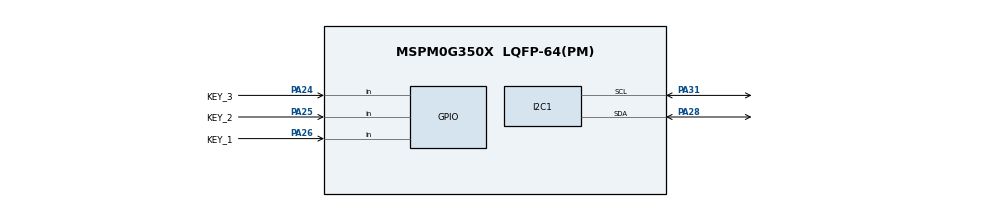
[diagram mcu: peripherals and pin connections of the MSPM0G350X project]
/**
 *
 * @cliArgs --device "MSPM0G350X" --part "Default" --package "LQFP-64(PM)" --product "mspm0_sdk@2.10.00.04"
 * @versions {"tool":"1.28.0+4696"}
 */

/**
 * Import the modules used in this configuration.
 */
const DMA     = scripting.addModule("/ti/driverlib/DMA");
const GPIO    = scripting.addModule("/ti/driverlib/GPIO", {}, false);
const GPIO1   = GPIO.addInstance();
const GPIO2   = GPIO.addInstance();
const GPIO3   = GPIO.addInstance();
const GPIO4   = GPIO.addInstance();
const GPIO5   = GPIO.addInstance();
const I2C     = scripting.addModule("/ti/driverlib/I2C", {}, false);
const I2C1    = I2C.addInstance();
const PWM     = scripting.addModule("/ti/driverlib/PWM", {}, false);
const PWM1    = PWM.addInstance();
const SYSCTL  = scripting.addModule("/ti/driverlib/SYSCTL");
const SYSTICK = scripting.addModule("/ti/driverlib/SYSTICK");
const TIMER   = scripting.addModule("/ti/driverlib/TIMER", {}, false);
const TIMER1  = TIMER.addInstance();
const UART    = scripting.addModule("/ti/driverlib/UART", {}, false);
const UART1   = UART.addInstance();
const UART2   = UART.addInstance();
const UART3   = UART.addInstance();
const UART4   = UART.addInstance();

/**
 * Write custom configuration values to the imported modules.
 */
const divider6       = system.clockTree["PLL_CLK2X_DIV"];
divider6.divideValue = 4;

const divider7       = system.clockTree["PLL_PDIV"];
divider7.divideValue = 2;

const divider9       = system.clockTree["UDIV"];
divider9.divideValue = 2;

const multiplier2         = system.clockTree["PLL_QDIV"];
multiplier2.multiplyValue = 10;

const mux8       = system.clockTree["HSCLKMUX"];
mux8.inputSelect = "HSCLKMUX_SYSPLL2X";

const Board = scripting.addModule("/ti/driverlib/Board", {}, false);

GPIO1.$name                         = "ENCODERA";
GPIO1.associatedPins.create(2);
GPIO1.associatedPins[0].$name       = "E1A";
GPIO1.associatedPins[0].direction   = "INPUT";
GPIO1.associatedPins[0].interruptEn = true;
GPIO1.associatedPins[0].polarity    = "RISE_FALL";
GPIO1.associatedPins[1].$name       = "E1B";
GPIO1.associatedPins[1].direction   = "INPUT";
GPIO1.associatedPins[1].interruptEn = true;
GPIO1.associatedPins[1].polarity    = "RISE_FALL";

GPIO2.$name                         = "ENCODERB";
GPIO2.associatedPins.create(2);
GPIO2.associatedPins[0].$name       = "E2A";
GPIO2.associatedPins[0].direction   = "INPUT";
GPIO2.associatedPins[0].interruptEn = true;
GPIO2.associatedPins[0].polarity    = "RISE_FALL";
GPIO2.associatedPins[1].$name       = "E2B";
GPIO2.associatedPins[1].direction   = "INPUT";
GPIO2.associatedPins[1].interruptEn = true;
GPIO2.associatedPins[1].polarity    = "RISE_FALL";

GPIO3.$name                   = "AIN";
GPIO3.associatedPins.create(2);
GPIO3.associatedPins[0].$name = "AIN1";
GPIO3.associatedPins[1].$name = "AIN2";

GPIO4.$name                   = "BIN";
GPIO4.associatedPins.create(2);
GPIO4.associatedPins[0].$name = "BIN1";
GPIO4.associatedPins[1].$name = "BIN2";

GPIO5.$name                              = "KEY";
GPIO5.port                               = "PORTA";
GPIO5.associatedPins.create(3);
GPIO5.associatedPins[0].$name            = "KEY_1";
GPIO5.associatedPins[0].direction        = "INPUT";
GPIO5.associatedPins[0].internalResistor = "PULL_UP";
GPIO5.associatedPins[0].pin.$assign      = "PA26";
GPIO5.associatedPins[1].$name            = "KEY_2";
GPIO5.associatedPins[1].direction        = "INPUT";
GPIO5.associatedPins[1].internalResistor = "PULL_UP";
GPIO5.associatedPins[1].pin.$assign      = "PA25";
GPIO5.associatedPins[2].$name            = "KEY_3";
GPIO5.associatedPins[2].direction        = "INPUT";
GPIO5.associatedPins[2].internalResistor = "PULL_UP";
GPIO5.associatedPins[2].pin.$assign      = "PA24";

I2C1.$name                             = "I2C_OLED";
I2C1.basicEnableController             = true;
I2C1.basicControllerStandardBusSpeed   = "Fast";
I2C1.peripheral.sdaPin.$assign         = "PA28";
I2C1.peripheral.sclPin.$assign         = "PA31";
I2C1.sdaPinConfig.$name                = "ti_driverlib_gpio_GPIOPinGeneric10";
I2C1.sdaPinConfig.hideOutputInversion  = scripting.forceWrite(false);
I2C1.sdaPinConfig.onlyInternalResistor = scripting.forceWrite(false);
I2C1.sdaPinConfig.passedPeripheralType = scripting.forceWrite("Digital");
I2C1.sclPinConfig.$name                = "ti_driverlib_gpio_GPIOPinGeneric11";
I2C1.sclPinConfig.hideOutputInversion  = scripting.forceWrite(false);
I2C1.sclPinConfig.onlyInternalResistor = scripting.forceWrite(false);
I2C1.sclPinConfig.passedPeripheralType = scripting.forceWrite("Digital");

PWM1.$name               = "PWM_0";
PWM1.timerCount          = 8000;
PWM1.timerStartTimer     = true;
PWM1.pwmMode             = "EDGE_ALIGN_UP";
PWM1.PWM_CHANNEL_0.$name = "ti_driverlib_pwm_PWMTimerCC0";
PWM1.PWM_CHANNEL_1.$name = "ti_driverlib_pwm_PWMTimerCC1";
PWM1.ccp0PinConfig.$name = "ti_driverlib_gpio_GPIOPinGeneric0";
PWM1.ccp1PinConfig.$name = "ti_driverlib_gpio_GPIOPinGeneric1";

SYSCTL.forceDefaultClkConfig = true;
SYSCTL.clockTreeEn           = true;

SYSTICK.periodEnable  = true;
SYSTICK.period        = 80;
SYSTICK.systickEnable = true;

TIMER1.timerMode         = "PERIODIC";
TIMER1.timerPeriod       = "1 ms";
TIMER1.timerClkPrescale  = 8;
TIMER1.interrupts        = ["ZERO"];
TIMER1.interruptPriority = "2";
TIMER1.$name             = "TIMER_1ms";

UART1.enabledDMARXTriggers             = "DL_UART_DMA_INTERRUPT_RX";
UART1.$name                            = "UART_fpgaMLK";
UART1.txPinConfig.$name                = "ti_driverlib_gpio_GPIOPinGeneric2";
UART1.txPinConfig.direction            = scripting.forceWrite("OUTPUT");
UART1.txPinConfig.hideOutputInversion  = scripting.forceWrite(false);
UART1.txPinConfig.onlyInternalResistor = scripting.forceWrite(false);
UART1.txPinConfig.passedPeripheralType = scripting.forceWrite("Digital");
UART1.rxPinConfig.$name                = "ti_driverlib_gpio_GPIOPinGeneric3";
UART1.rxPinConfig.hideOutputInversion  = scripting.forceWrite(false);
UART1.rxPinConfig.onlyInternalResistor = scripting.forceWrite(false);
UART1.rxPinConfig.passedPeripheralType = scripting.forceWrite("Digital");
UART1.DMA_CHANNEL_RX.$name             = "DMA_fpgaMLK";

UART2.$name                            = "UART_left";
UART2.targetBaudRate                   = 115200;
UART2.enableFIFO                       = true;
UART2.enabledInterrupts                = ["FRAMING_ERROR","NOISE_ERROR","OVERRUN_ERROR","RX"];
UART2.rxFifoThreshold                  = "DL_UART_RX_FIFO_LEVEL_ONE_ENTRY";
UART2.txPinConfig.$name                = "ti_driverlib_gpio_GPIOPinGeneric4";
UART2.txPinConfig.direction            = scripting.forceWrite("OUTPUT");
UART2.txPinConfig.hideOutputInversion  = scripting.forceWrite(false);
UART2.txPinConfig.onlyInternalResistor = scripting.forceWrite(false);
UART2.txPinConfig.passedPeripheralType = scripting.forceWrite("Digital");
UART2.rxPinConfig.$name                = "ti_driverlib_gpio_GPIOPinGeneric5";
UART2.rxPinConfig.hideOutputInversion  = scripting.forceWrite(false);
UART2.rxPinConfig.onlyInternalResistor = scripting.forceWrite(false);
UART2.rxPinConfig.passedPeripheralType = scripting.forceWrite("Digital");

UART3.$name                            = "UART_forward";
UART3.targetBaudRate                   = 115200;
UART3.enableFIFO                       = true;
UART3.enabledInterrupts                = ["FRAMING_ERROR","NOISE_ERROR","OVERRUN_ERROR","RX"];
UART3.rxFifoThreshold                  = "DL_UART_RX_FIFO_LEVEL_ONE_ENTRY";
UART3.txPinConfig.$name                = "ti_driverlib_gpio_GPIOPinGeneric6";
UART3.txPinConfig.direction            = scripting.forceWrite("OUTPUT");
UART3.txPinConfig.hideOutputInversion  = scripting.forceWrite(false);
UART3.txPinConfig.onlyInternalResistor = scripting.forceWrite(false);
UART3.txPinConfig.passedPeripheralType = scripting.forceWrite("Digital");
UART3.rxPinConfig.$name                = "ti_driverlib_gpio_GPIOPinGeneric7";
UART3.rxPinConfig.hideOutputInversion  = scripting.forceWrite(false);
UART3.rxPinConfig.onlyInternalResistor = scripting.forceWrite(false);
UART3.rxPinConfig.passedPeripheralType = scripting.forceWrite("Digital");

UART4.$name                            = "UART_right";
UART4.targetBaudRate                   = 115200;
UART4.enableFIFO                       = true;
UART4.enabledInterrupts                = ["FRAMING_ERROR","NOISE_ERROR","OVERRUN_ERROR","RX"];
UART4.rxFifoThreshold                  = "DL_UART_RX_FIFO_LEVEL_ONE_ENTRY";
UART4.txPinConfig.$name                = "ti_driverlib_gpio_GPIOPinGeneric8";
UART4.txPinConfig.direction            = scripting.forceWrite("OUTPUT");
UART4.txPinConfig.hideOutputInversion  = scripting.forceWrite(false);
UART4.txPinConfig.onlyInternalResistor = scripting.forceWrite(false);
UART4.txPinConfig.passedPeripheralType = scripting.forceWrite("Digital");
UART4.rxPinConfig.$name                = "ti_driverlib_gpio_GPIOPinGeneric9";
UART4.rxPinConfig.hideOutputInversion  = scripting.forceWrite(false);
UART4.rxPinConfig.onlyInternalResistor = scripting.forceWrite(false);
UART4.rxPinConfig.passedPeripheralType = scripting.forceWrite("Digital");

/**
 * Pinmux solution for unlocked pins/peripherals. This ensures that minor changes to the automatic solver in a future
 * version of the tool will not impact the pinmux you originally saw.  These lines can be completely deleted in order to
 * re-solve from scratch.
 */
Board.peripheral.$suggestSolution                = "DEBUGSS";
Board.peripheral.swclkPin.$suggestSolution       = "PA20";
Board.peripheral.swdioPin.$suggestSolution       = "PA19";
GPIO1.associatedPins[0].pin.$suggestSolution     = "PB13";
GPIO1.associatedPins[1].pin.$suggestSolution     = "PB14";
GPIO2.associatedPins[0].pin.$suggestSolution     = "PB15";
GPIO2.associatedPins[1].pin.$suggestSolution     = "PB16";
GPIO3.associatedPins[0].pin.$suggestSolution     = "PA12";
GPIO3.associatedPins[1].pin.$suggestSolution     = "PA15";
GPIO4.associatedPins[0].pin.$suggestSolution     = "PA16";
GPIO4.associatedPins[1].pin.$suggestSolution     = "PB17";
I2C1.peripheral.$suggestSolution                 = "I2C0";
PWM1.peripheral.$suggestSolution                 = "TIMA1";
PWM1.peripheral.ccp0Pin.$suggestSolution         = "PA10";
PWM1.peripheral.ccp1Pin.$suggestSolution         = "PA11";
TIMER1.peripheral.$suggestSolution               = "TIMA0";
UART1.peripheral.$suggestSolution                = "UART3";
UART1.peripheral.rxPin.$suggestSolution          = "PA13";
UART1.peripheral.txPin.$suggestSolution          = "PA14";
UART1.DMA_CHANNEL_RX.peripheral.$suggestSolution = "DMA_CH0";
UART2.peripheral.$suggestSolution                = "UART2";
UART2.peripheral.rxPin.$suggestSolution          = "PA22";
UART2.peripheral.txPin.$suggestSolution          = "PA21";
UART3.peripheral.$suggestSolution                = "UART1";
UART3.peripheral.rxPin.$suggestSolution          = "PA18";
UART3.peripheral.txPin.$suggestSolution          = "PA17";
UART4.peripheral.$suggestSolution                = "UART0";
UART4.peripheral.rxPin.$suggestSolution          = "PA1";
UART4.peripheral.txPin.$suggestSolution          = "PA0";
